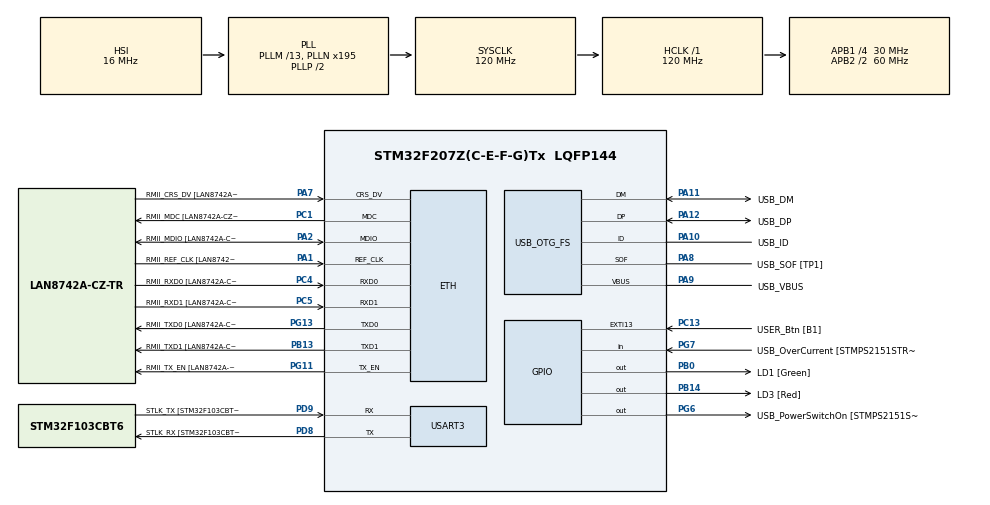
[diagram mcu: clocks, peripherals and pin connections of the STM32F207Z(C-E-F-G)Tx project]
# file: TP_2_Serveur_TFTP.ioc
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ETH.MediaInterface=ETH_MEDIA_INTERFACE_RMII
ETH.PHY_Name=LAN8742A_PHY_ADDRESS
ETH.PHY_Value=0
ETH.PhyAddress=0
FREERTOS.Tasks01=defaultTask,0,1024,StartDefaultTask,Default,NULL,Dynamic,NULL,NULL
FREERTOS.configMINIMAL_STACK_SIZE=1024
LWIP.IP_ADDRESS=169.254.103.111
LWIP.LWIP_DHCP=0
LWIP.NETMASK_ADDRESS=255.255.000.000
LWIP.RTOS_USE_NEWLIB_REENTRANT=FREERTOS$context\:USE_NEWLIB_REENTRANT
LWIP.Version=v2.0.3_Cube
Mcu.Family=STM32F2
Mcu.Name=STM32F207Z(C-E-F-G)Tx
Mcu.Package=LQFP144
NVIC.ETH_IRQn=true\:5\:0\:false\:false\:true\:true\:false\:true\:true
NVIC.PriorityGroup=NVIC_PRIORITYGROUP_4
PA1.GPIO_Label=RMII_REF_CLK [LAN8742A-CZ-TR_REFCLK0]
PA1.Mode=RMII
PA1.Signal=ETH_REF_CLK
PA10.GPIO_Label=USB_ID
PA10.Mode=OTG/Dual_Role_Device
PA10.Signal=USB_OTG_FS_ID
PA11.GPIO_Label=USB_DM
PA11.Mode=OTG/Dual_Role_Device
PA11.Signal=USB_OTG_FS_DM
PA12.GPIO_Label=USB_DP
PA12.Mode=OTG/Dual_Role_Device
PA12.Signal=USB_OTG_FS_DP
PA13.GPIO_Label=TMS
PA13.Mode=Serial_Wire
PA13.Signal=SYS_JTMS-SWDIO
PA14.GPIO_Label=TCK
PA14.Mode=Serial_Wire
PA14.Signal=SYS_JTCK-SWCLK
PA2.GPIO_Label=RMII_MDIO [LAN8742A-CZ-TR_MDIO]
PA2.Mode=RMII
PA2.Signal=ETH_MDIO
PA7.GPIO_Label=RMII_CRS_DV [LAN8742A-CZ-TR_CRS_DV]
PA7.Mode=RMII
PA7.Signal=ETH_CRS_DV
PA8.GPIO_Label=USB_SOF [TP1]
PA8.Mode=Activate_SOF_FS
PA8.Signal=USB_OTG_FS_SOF
PA9.GPIO_Label=USB_VBUS
PA9.Mode=Activate_VBUS
PA9.Signal=USB_OTG_FS_VBUS
PB0.GPIO_Label=LD1 [Green]
PB0.Signal=GPIO_Output
PB13.GPIO_Label=RMII_TXD1 [LAN8742A-CZ-TR_TXD1]
PB13.Mode=RMII
PB13.Signal=ETH_TXD1
PB14.GPIO_Label=LD3 [Red]
PB14.Signal=GPIO_Output
PB3.GPIO_Label=SWO
PB3.Signal=SYS_JTDO-SWO
PB7.Signal=USART1_RX
PC1.GPIO_Label=RMII_MDC [LAN8742A-CZ-TR_MDC]
PC1.Mode=RMII
PC1.Signal=ETH_MDC
PC13.GPIO_Label=USER_Btn [B1]
PC13.Signal=GPXTI13
PC14-OSC32_IN.Mode=LSE-External-Oscillator
PC14-OSC32_IN.Signal=RCC_OSC32_IN
PC15-OSC32_OUT.Mode=LSE-External-Oscillator
PC15-OSC32_OUT.Signal=RCC_OSC32_OUT
PC4.GPIO_Label=RMII_RXD0 [LAN8742A-CZ-TR_RXD0]
PC4.Mode=RMII
PC4.Signal=ETH_RXD0
PC5.GPIO_Label=RMII_RXD1 [LAN8742A-CZ-TR_RXD1]
PC5.Mode=RMII
PC5.Signal=ETH_RXD1
PD8.GPIO_Label=STLK_RX [STM32F103CBT6_PA3]
PD8.Mode=Asynchronous
PD8.Signal=USART3_TX
PD9.GPIO_Label=STLK_TX [STM32F103CBT6_PA2]
PD9.Mode=Asynchronous
PD9.Signal=USART3_RX
PG11.GPIO_Label=RMII_TX_EN [LAN8742A-CZ-TR_TXEN]
PG11.Mode=RMII
PG11.Signal=ETH_TX_EN
PG13.GPIO_Label=RMII_TXD0 [LAN8742A-CZ-TR_TXD0]
PG13.Mode=RMII
PG13.Signal=ETH_TXD0
PG6.GPIO_Label=USB_PowerSwitchOn [STMPS2151STR_EN]
PG6.Signal=GPIO_Output
PG7.GPIO_Label=USB_OverCurrent [STMPS2151STR_FAULT]
PG7.Signal=GPIO_Input
PH0-OSC_IN.GPIO_Label=MCO [STM32F103CBT6_PA8]
PH0-OSC_IN.Mode=HSE-External-Clock-Source
PH0-OSC_IN.Signal=RCC_OSC_IN
PH1-OSC_OUT.Mode=HSE-External-Clock-Source
PH1-OSC_OUT.Signal=RCC_OSC_OUT
ProjectManager.HeapSize=0x200
ProjectManager.StackSize=0x400
ProjectManager.TargetToolchain=STM32CubeIDE
RCC.48MHZClocksFreq_Value=48000000
RCC.AHBFreq_Value=120000000
RCC.APB1CLKDivider=RCC_HCLK_DIV4
RCC.APB1Freq_Value=30000000
RCC.APB1TimFreq_Value=60000000
RCC.APB2CLKDivider=RCC_HCLK_DIV2
RCC.APB2Freq_Value=60000000
RCC.APB2TimFreq_Value=120000000
RCC.CortexFreq_Value=120000000
RCC.HCLKFreq_Value=120000000
RCC.HSE_VALUE=8000000
RCC.HSI_VALUE=16000000
RCC.PLLM=13
RCC.PLLMUL=RCC_PLL_MUL9
RCC.PLLN=195
RCC.PLLQ=5
RCC.PRESCALERUSB=RCC_USBCLKSOURCE_PLL_DIV1_5
RCC.SYSCLKFreq_VALUE=120000000
RCC.SYSCLKSource=RCC_SYSCLKSOURCE_PLLCLK
RCC.SYSCLKSourceVirtual=RCC_SYSCLKSOURCE_PLLCLK
RCC.USBFreq_Value=48000000
RCC.VCOOutputFreq_Value=240000000
USART3.VirtualMode=VM_ASYNC
VP_FREERTOS_VS_CMSIS_V1.Mode=CMSIS_V1
VP_LWIP_VS_Enabled.Mode=Enabled
board=NUCLEO-F207ZG

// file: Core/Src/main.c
/* USER CODE BEGIN Header */
/**
 ******************************************************************************
 * @file           : main.c
 * @brief          : Main program body
 ******************************************************************************
 * @attention
 *
 * Copyright (c) 2022 STMicroelectronics.
 * All rights reserved.
 *
 * This software is licensed under terms that can be found in the LICENSE file
 * in the root directory of this software component.
 * If no LICENSE file comes with this software, it is provided AS-IS.
 *
 ******************************************************************************
 */
/* USER CODE END Header */
#include "main.h"
#include "cmsis_os.h"
#include "lwip.h"
#include "usart.h"
#include "usb_otg.h"
#include "gpio.h"

void SystemClock_Config(void);
void MX_FREERTOS_Init(void);

int main(void)
{

  /* MCU Configuration--------------------------------------------------------*/

  /* Reset of all peripherals, Initializes the Flash interface and the Systick. */
  HAL_Init();

  /* Configure the system clock */
  SystemClock_Config();

  /* Initialize all configured peripherals */
  MX_GPIO_Init();
  MX_USART3_UART_Init();
  MX_USB_OTG_FS_USB_Init();

  /* Call init function for freertos objects (in freertos.c) */
  MX_FREERTOS_Init();

  /* Start scheduler */
  osKernelStart();

  /* We should never get here as control is now taken by the scheduler */
  /* Infinite loop */
  while (1)
  {

  }
}

void SystemClock_Config(void)
{
  RCC_OscInitTypeDef RCC_OscInitStruct = {0};
  RCC_ClkInitTypeDef RCC_ClkInitStruct = {0};

  /** Initializes the RCC Oscillators according to the specified parameters
  * in the RCC_OscInitTypeDef structure.
  */
  RCC_OscInitStruct.OscillatorType = RCC_OSCILLATORTYPE_HSI;
  RCC_OscInitStruct.HSIState = RCC_HSI_ON;
  RCC_OscInitStruct.HSICalibrationValue = RCC_HSICALIBRATION_DEFAULT;
  RCC_OscInitStruct.PLL.PLLState = RCC_PLL_ON;
  RCC_OscInitStruct.PLL.PLLSource = RCC_PLLSOURCE_HSI;
  RCC_OscInitStruct.PLL.PLLM = 13;
  RCC_OscInitStruct.PLL.PLLN = 195;
  RCC_OscInitStruct.PLL.PLLP = RCC_PLLP_DIV2;
  RCC_OscInitStruct.PLL.PLLQ = 5;
  if (HAL_RCC_OscConfig(&RCC_OscInitStruct) != HAL_OK)
  {
    Error_Handler();
  }

  /** Initializes the CPU, AHB and APB buses clocks
  */
  RCC_ClkInitStruct.ClockType = RCC_CLOCKTYPE_HCLK|RCC_CLOCKTYPE_SYSCLK
                              |RCC_CLOCKTYPE_PCLK1|RCC_CLOCKTYPE_PCLK2;
  RCC_ClkInitStruct.SYSCLKSource = RCC_SYSCLKSOURCE_PLLCLK;
  RCC_ClkInitStruct.AHBCLKDivider = RCC_SYSCLK_DIV1;
  RCC_ClkInitStruct.APB1CLKDivider = RCC_HCLK_DIV4;
  RCC_ClkInitStruct.APB2CLKDivider = RCC_HCLK_DIV2;

  if (HAL_RCC_ClockConfig(&RCC_ClkInitStruct, FLASH_LATENCY_3) != HAL_OK)
  {
    Error_Handler();
  }
}

void Error_Handler(void)
{
  __disable_irq();
  while (1)
  {
  }
}

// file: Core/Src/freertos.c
/* USER CODE BEGIN Header */
/**
  ******************************************************************************
  * File Name          : freertos.c
  * Description        : Code for freertos applications
  ******************************************************************************
  * @attention
  *
  * Copyright (c) 2022 STMicroelectronics.
  * All rights reserved.
  *
  * This software is licensed under terms that can be found in the LICENSE file
  * in the root directory of this software component.
  * If no LICENSE file comes with this software, it is provided AS-IS.
  *
  ******************************************************************************
  */
/* USER CODE END Header */

#include "FreeRTOS.h"
#include "task.h"
#include "main.h"
#include "cmsis_os.h"
#include "tftp_server.h"
#include "usart.h"

osThreadId defaultTaskHandle;

void StartDefaultTask(void const * argument);

extern void MX_LWIP_Init(void);
void MX_FREERTOS_Init(void); /* (MISRA C 2004 rule 8.1) */

/* GetIdleTaskMemory prototype (linked to static allocation support) */
void vApplicationGetIdleTaskMemory( StaticTask_t **ppxIdleTaskTCBBuffer, StackType_t **ppxIdleTaskStackBuffer, uint32_t *pulIdleTaskStackSize );

/* USER CODE BEGIN GET_IDLE_TASK_MEMORY */
static StaticTask_t xIdleTaskTCBBuffer;
static StackType_t xIdleStack[configMINIMAL_STACK_SIZE];

void vApplicationGetIdleTaskMemory( StaticTask_t **ppxIdleTaskTCBBuffer, StackType_t **ppxIdleTaskStackBuffer, uint32_t *pulIdleTaskStackSize )
{
  *ppxIdleTaskTCBBuffer = &xIdleTaskTCBBuffer;
  *ppxIdleTaskStackBuffer = &xIdleStack[0];
  *pulIdleTaskStackSize = configMINIMAL_STACK_SIZE;
  /* place for user code */
}
/* USER CODE END GET_IDLE_TASK_MEMORY */

void MX_FREERTOS_Init(void) {

  /* Create the thread(s) */
  /* definition and creation of defaultTask */
  osThreadDef(defaultTask, StartDefaultTask, osPriorityNormal, 0, 1024);
  defaultTaskHandle = osThreadCreate(osThread(defaultTask), NULL);

}

void StartDefaultTask(void const * argument)
{
  /* init code for LWIP */
    MX_LWIP_Init();
    uint8_t MSG[35] = {'\0'};
    uint8_t X = 0;
    X = tftp_server_init();
    if (X == 8) {
        for (int i = 0; i < 8; ++i) {
            HAL_GPIO_TogglePin(GPIOB, GPIO_PIN_0);//Toggle LED_1 GREEN
            HAL_Delay(100);
        }
    } else {
        HAL_GPIO_WritePin(GPIOB, GPIO_PIN_14, GPIO_PIN_SET);//Toggle LED_3 RED
    }
    sprintf(MSG, " tftp_server_init return = %d\r\n", X);
    HAL_UART_Transmit(&huart3, MSG, sizeof(MSG), 100);

  /* USER CODE BEGIN StartDefaultTask */
  /* Infinite loop */
  for(;;)
  {
      tftp_server_run();
  }
  /* USER CODE END StartDefaultTask */
}
